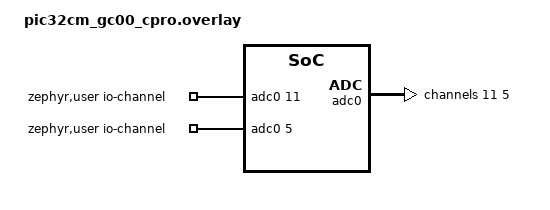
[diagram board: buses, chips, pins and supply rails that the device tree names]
/*
 * Copyright (c) 2026 Arkadiusz Grzelka
 *
 * SPDX-License-Identifier: Apache-2.0
 */

#include <zephyr/dt-bindings/adc/adc.h>

/ {
	zephyr,user {
		io-channels = <&adc0 11>, <&adc0 5>;
	};
};

&adc0 {
	channel@b {
		reg = <0xb>;
		zephyr,gain = "ADC_GAIN_1";
		zephyr,reference = "ADC_REF_EXTERNAL0";
		zephyr,acquisition-time = <ADC_ACQ_TIME_DEFAULT>;
		zephyr,resolution = <12>;
	};

	channel@5 {
		reg = <0x5>;
		zephyr,gain = "ADC_GAIN_1";
		zephyr,reference = "ADC_REF_EXTERNAL0";
		zephyr,acquisition-time = <ADC_ACQ_TIME_DEFAULT>;
		zephyr,resolution = <12>;
	};
};
